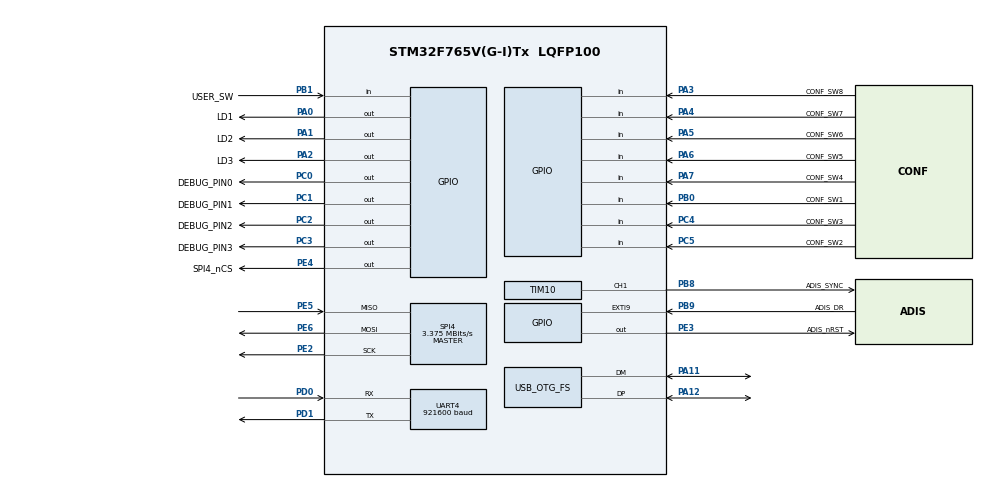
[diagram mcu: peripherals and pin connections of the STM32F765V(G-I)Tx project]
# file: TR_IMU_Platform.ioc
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CORTEX_M7.CPU_DCache=Disabled
CORTEX_M7.CPU_ICache=Enabled
CORTEX_M7.PREFETCH_ENABLE=0
Dma.Request0=UART4_RX
Dma.Request1=UART4_TX
Dma.Request2=SPI4_RX
Dma.SPI4_RX.2.Direction=DMA_PERIPH_TO_MEMORY
Dma.SPI4_RX.2.FIFOMode=DMA_FIFOMODE_DISABLE
Dma.SPI4_RX.2.Instance=DMA2_Stream0
Dma.SPI4_RX.2.MemDataAlignment=DMA_MDATAALIGN_HALFWORD
Dma.SPI4_RX.2.MemInc=DMA_MINC_ENABLE
Dma.SPI4_RX.2.Mode=DMA_NORMAL
Dma.SPI4_RX.2.PeriphDataAlignment=DMA_PDATAALIGN_HALFWORD
Dma.SPI4_RX.2.PeriphInc=DMA_PINC_DISABLE
Dma.SPI4_RX.2.Priority=DMA_PRIORITY_HIGH
Dma.UART4_RX.0.Direction=DMA_PERIPH_TO_MEMORY
Dma.UART4_RX.0.FIFOMode=DMA_FIFOMODE_DISABLE
Dma.UART4_RX.0.Instance=DMA1_Stream2
Dma.UART4_RX.0.MemDataAlignment=DMA_MDATAALIGN_BYTE
Dma.UART4_RX.0.MemInc=DMA_MINC_ENABLE
Dma.UART4_RX.0.Mode=DMA_CIRCULAR
Dma.UART4_RX.0.PeriphDataAlignment=DMA_PDATAALIGN_BYTE
Dma.UART4_RX.0.PeriphInc=DMA_PINC_DISABLE
Dma.UART4_RX.0.Priority=DMA_PRIORITY_HIGH
Dma.UART4_TX.1.Direction=DMA_MEMORY_TO_PERIPH
Dma.UART4_TX.1.FIFOMode=DMA_FIFOMODE_DISABLE
Dma.UART4_TX.1.Instance=DMA1_Stream4
Dma.UART4_TX.1.MemDataAlignment=DMA_MDATAALIGN_BYTE
Dma.UART4_TX.1.MemInc=DMA_MINC_ENABLE
Dma.UART4_TX.1.Mode=DMA_NORMAL
Dma.UART4_TX.1.PeriphDataAlignment=DMA_PDATAALIGN_BYTE
Dma.UART4_TX.1.PeriphInc=DMA_PINC_DISABLE
Dma.UART4_TX.1.Priority=DMA_PRIORITY_LOW
IWDG.Prescaler=IWDG_PRESCALER_16
Mcu.Family=STM32F7
Mcu.Name=STM32F765V(G-I)Tx
Mcu.Package=LQFP100
NVIC.DMA1_Stream2_IRQn=true\:3\:0\:true\:false\:true\:false\:true\:true
NVIC.DMA1_Stream4_IRQn=true\:3\:0\:true\:false\:true\:false\:true\:true
NVIC.DMA2_Stream0_IRQn=true\:0\:0\:false\:false\:true\:false\:true\:true
NVIC.EXTI9_5_IRQn=true\:2\:0\:true\:false\:true\:true\:true\:true
NVIC.OTG_FS_IRQn=true\:0\:0\:false\:false\:true\:false\:true\:true
NVIC.PriorityGroup=NVIC_PRIORITYGROUP_4
NVIC.UART4_IRQn=true\:1\:0\:true\:false\:true\:true\:true\:true
PA0/WKUP.GPIO_Label=LD1
PA0/WKUP.GPIO_ModeDefaultOutputPP=GPIO_MODE_OUTPUT_OD
PA0/WKUP.GPIO_PuPd=GPIO_NOPULL
PA0/WKUP.GPIO_Speed=GPIO_SPEED_FREQ_VERY_HIGH
PA0/WKUP.PinState=GPIO_PIN_SET
PA0/WKUP.Signal=GPIO_Output
PA1.GPIO_Label=LD2
PA1.GPIO_ModeDefaultOutputPP=GPIO_MODE_OUTPUT_OD
PA1.GPIO_PuPd=GPIO_NOPULL
PA1.GPIO_Speed=GPIO_SPEED_FREQ_VERY_HIGH
PA1.PinState=GPIO_PIN_SET
PA1.Signal=GPIO_Output
PA11.Mode=Device_Only
PA11.Signal=USB_OTG_FS_DM
PA12.Mode=Device_Only
PA12.Signal=USB_OTG_FS_DP
PA13.Mode=Serial_Wire
PA13.Signal=SYS_JTMS-SWDIO
PA14.Mode=Serial_Wire
PA14.Signal=SYS_JTCK-SWCLK
PA2.GPIO_Label=LD3
PA2.GPIO_ModeDefaultOutputPP=GPIO_MODE_OUTPUT_OD
PA2.GPIO_PuPd=GPIO_NOPULL
PA2.GPIO_Speed=GPIO_SPEED_FREQ_VERY_HIGH
PA2.PinState=GPIO_PIN_SET
PA2.Signal=GPIO_Output
PA3.GPIO_Label=CONF_SW8
PA3.GPIO_Mode=GPIO_MODE_INPUT
PA3.GPIO_PuPd=GPIO_NOPULL
PA3.Signal=GPIO_Input
PA4.GPIO_Label=CONF_SW7
PA4.GPIO_Mode=GPIO_MODE_INPUT
PA4.GPIO_PuPd=GPIO_NOPULL
PA4.Signal=GPIO_Input
PA5.GPIO_Label=CONF_SW6
PA5.GPIO_Mode=GPIO_MODE_INPUT
PA5.GPIO_PuPd=GPIO_NOPULL
PA5.Signal=GPIO_Input
PA6.GPIO_Label=CONF_SW5
PA6.GPIO_Mode=GPIO_MODE_INPUT
PA6.GPIO_PuPd=GPIO_NOPULL
PA6.Signal=GPIO_Input
PA7.GPIO_Label=CONF_SW4
PA7.GPIO_Mode=GPIO_MODE_INPUT
PA7.GPIO_PuPd=GPIO_NOPULL
PA7.Signal=GPIO_Input
PB0.GPIO_Label=CONF_SW1
PB0.GPIO_Mode=GPIO_MODE_INPUT
PB0.GPIO_PuPd=GPIO_NOPULL
PB0.Signal=GPIO_Input
PB1.GPIO_Label=USER_SW
PB1.Signal=GPIO_Input
PB8.GPIO_Label=ADIS_SYNC
PB8.GPIO_Speed=GPIO_SPEED_FREQ_VERY_HIGH
PB8.Signal=S_TIM10_CH1
PB9.GPIO_Label=ADIS_DR
PB9.GPIO_PuPd=GPIO_PULLUP
PB9.Signal=GPXTI9
PC0.GPIO_Label=DEBUG_PIN0
PC0.GPIO_Speed=GPIO_SPEED_FREQ_VERY_HIGH
PC0.Signal=GPIO_Output
PC1.GPIO_Label=DEBUG_PIN1
PC1.GPIO_Speed=GPIO_SPEED_FREQ_VERY_HIGH
PC1.Signal=GPIO_Output
PC2.GPIO_Label=DEBUG_PIN2
PC2.GPIO_Speed=GPIO_SPEED_FREQ_VERY_HIGH
PC2.Signal=GPIO_Output
PC3.GPIO_Label=DEBUG_PIN3
PC3.GPIO_Speed=GPIO_SPEED_FREQ_VERY_HIGH
PC3.Signal=GPIO_Output
PC4.GPIO_Label=CONF_SW3
PC4.Signal=GPIO_Input
PC5.GPIO_Label=CONF_SW2
PC5.Signal=GPIO_Input
PD0.Mode=Asynchronous
PD0.Signal=UART4_RX
PD1.Mode=Asynchronous
PD1.Signal=UART4_TX
PE2.Mode=Full_Duplex_Master
PE2.Signal=SPI4_SCK
PE3.GPIO_Label=ADIS_nRST
PE3.GPIO_Speed=GPIO_SPEED_FREQ_VERY_HIGH
PE3.PinState=GPIO_PIN_SET
PE3.Signal=GPIO_Output
PE4.GPIO_Label=SPI4_nCS
PE4.GPIO_Speed=GPIO_SPEED_FREQ_VERY_HIGH
PE4.PinState=GPIO_PIN_SET
PE4.Signal=GPIO_Output
PE5.Mode=Full_Duplex_Master
PE5.Signal=SPI4_MISO
PE6.Mode=Full_Duplex_Master
PE6.Signal=SPI4_MOSI
PH0/OSC_IN.Mode=HSE-External-Oscillator
PH0/OSC_IN.Signal=RCC_OSC_IN
PH1/OSC_OUT.Mode=HSE-External-Oscillator
PH1/OSC_OUT.Signal=RCC_OSC_OUT
ProjectManager.HeapSize=0x400
ProjectManager.StackSize=0x400
ProjectManager.TargetToolchain=STM32CubeIDE
RCC.AHBFreq_Value=216000000
RCC.APB1CLKDivider=RCC_HCLK_DIV4
RCC.APB1Freq_Value=54000000
RCC.APB1TimFreq_Value=108000000
RCC.APB2CLKDivider=RCC_HCLK_DIV2
RCC.APB2Freq_Value=108000000
RCC.APB2TimFreq_Value=216000000
RCC.CortexFreq_Value=216000000
RCC.HCLKFreq_Value=216000000
RCC.HSE_VALUE=8000000
RCC.HSI_VALUE=16000000
RCC.LSE_VALUE=32768
RCC.PLL48CLockSelection=RCC_CLK48SOURCE_PLLSAIP
RCC.PLLM=4
RCC.PLLN=216
RCC.PLLQ=9
RCC.PLLSAIN=96
RCC.PLLSAIP=RCC_PLLSAIP_DIV4
RCC.SYSCLKFreq_VALUE=216000000
RCC.SYSCLKSource=RCC_SYSCLKSOURCE_PLLCLK
RCC.USBFreq_Value=48000000
RCC.VCOOutputFreq_Value=432000000
SH.S_TIM10_CH1.0=TIM10_CH1,PWM Generation1 CH1
SPI4.BaudRatePrescaler=SPI_BAUDRATEPRESCALER_32
SPI4.CLKPhase=SPI_PHASE_2EDGE
SPI4.CLKPolarity=SPI_POLARITY_HIGH
SPI4.CalculateBaudRate=3.375 MBits/s
SPI4.DataSize=SPI_DATASIZE_16BIT
SPI4.Direction=SPI_DIRECTION_2LINES
SPI4.Mode=SPI_MODE_MASTER
SPI4.VirtualType=VM_MASTER
TIM10.AutoReloadPreload=TIM_AUTORELOAD_PRELOAD_ENABLE
TIM10.Channel=TIM_CHANNEL_1
TIM10.Period=26999
TIM10.Prescaler=1
UART4.BaudRate=921600
USB_DEVICE.CLASS_NAME_FS=CDC
USB_DEVICE.VirtualMode-CDC_FS=Cdc
USB_DEVICE.VirtualModeFS=Cdc_FS
USB_OTG_FS.VirtualMode=Device_Only
VP_IWDG_VS_IWDG.Mode=IWDG_Activate
VP_TIM10_VS_ClockSourceINT.Mode=Enable_Timer
VP_USB_DEVICE_VS_USB_DEVICE_CDC_FS.Mode=CDC_FS
board=custom

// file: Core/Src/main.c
/* USER CODE BEGIN Header */
/**
  ******************************************************************************
  * @file           : main.c
  * @brief          : Main program body
  ******************************************************************************
  * @attention
  *
  * Copyright (c) 2023 STMicroelectronics.
  * All rights reserved.
  *
  * This software is licensed under terms that can be found in the LICENSE file
  * in the root directory of this software component.
  * If no LICENSE file comes with this software, it is provided AS-IS.
  *
  ******************************************************************************
  */
/* USER CODE END Header */
#include "main.h"
#include "usb_device.h"

/* USER CODE BEGIN Includes */
#include "libraries.h"
/* USER CODE END Includes */

void SystemClock_Config(void);
void PeriphCommonClock_Config(void);
static void MX_GPIO_Init(void);
static void MX_DMA_Init(void);
static void MX_SPI4_Init(void);
static void MX_UART4_Init(void);
static void MX_TIM10_Init(void);

int main(void)
{

  /* Enable the CPU Cache */

  /* Enable I-Cache---------------------------------------------------------*/
  SCB_EnableICache();

  /* MCU Configuration--------------------------------------------------------*/

  /* Reset of all peripherals, Initializes the Flash interface and the Systick. */
  HAL_Init();

  /* Configure the system clock */
  SystemClock_Config();

  /* Configure the peripherals common clocks */
  PeriphCommonClock_Config();

  /* Initialize all configured peripherals */
  MX_GPIO_Init();
  MX_DMA_Init();
  MX_SPI4_Init();
  MX_USB_DEVICE_Init();
  MX_UART4_Init();
  MX_TIM10_Init();
  /* USER CODE BEGIN 2 */
  EXTI_Stop();
  setup();
  /* USER CODE END 2 */

  /* Infinite loop */
  /* USER CODE BEGIN WHILE */
  while (1)
  {
    loop();
    /* USER CODE END WHILE */

  }
}

void SystemClock_Config(void)
{
  LL_FLASH_SetLatency(LL_FLASH_LATENCY_7);
  while(LL_FLASH_GetLatency()!= LL_FLASH_LATENCY_7)
  {
  }
  LL_PWR_SetRegulVoltageScaling(LL_PWR_REGU_VOLTAGE_SCALE1);
  LL_PWR_EnableOverDriveMode();
  LL_RCC_HSE_Enable();

   /* Wait till HSE is ready */
  while(LL_RCC_HSE_IsReady() != 1)
  {

  }
  LL_RCC_LSI_Enable();

   /* Wait till LSI is ready */
  while(LL_RCC_LSI_IsReady() != 1)
  {

  }
  LL_RCC_PLL_ConfigDomain_SYS(LL_RCC_PLLSOURCE_HSE, LL_RCC_PLLM_DIV_4, 216, LL_RCC_PLLP_DIV_2);
  LL_RCC_PLL_Enable();

   /* Wait till PLL is ready */
  while(LL_RCC_PLL_IsReady() != 1)
  {

  }
  while (LL_PWR_IsActiveFlag_VOS() == 0)
  {
  }
  LL_RCC_SetAHBPrescaler(LL_RCC_SYSCLK_DIV_1);
  LL_RCC_SetAPB1Prescaler(LL_RCC_APB1_DIV_4);
  LL_RCC_SetAPB2Prescaler(LL_RCC_APB2_DIV_2);
  LL_RCC_SetSysClkSource(LL_RCC_SYS_CLKSOURCE_PLL);

   /* Wait till System clock is ready */
  while(LL_RCC_GetSysClkSource() != LL_RCC_SYS_CLKSOURCE_STATUS_PLL)
  {

  }
  LL_SetSystemCoreClock(216000000);

   /* Update the time base */
  if (HAL_InitTick (TICK_INT_PRIORITY) != HAL_OK)
  {
    Error_Handler();
  }

   /* Set Timers Clock Prescalers */
  LL_RCC_SetTIMPrescaler(LL_RCC_TIM_PRESCALER_TWICE);
}

void PeriphCommonClock_Config(void)
{
  LL_RCC_PLLSAI_ConfigDomain_48M(LL_RCC_PLLSOURCE_HSE, LL_RCC_PLLM_DIV_4, 96, LL_RCC_PLLSAIP_DIV_4);
  LL_RCC_PLLSAI_Enable();

   /* Wait till PLL is ready */
  while(LL_RCC_PLLSAI_IsReady() != 1)
  {

  }
}

static void MX_SPI4_Init(void)
{

  LL_SPI_InitTypeDef SPI_InitStruct = {0};

  LL_GPIO_InitTypeDef GPIO_InitStruct = {0};

  /* Peripheral clock enable */
  LL_APB2_GRP1_EnableClock(LL_APB2_GRP1_PERIPH_SPI4);

  LL_AHB1_GRP1_EnableClock(LL_AHB1_GRP1_PERIPH_GPIOE);
  /**SPI4 GPIO Configuration
  PE2   ------> SPI4_SCK
  PE5   ------> SPI4_MISO
  PE6   ------> SPI4_MOSI
  */
  GPIO_InitStruct.Pin = LL_GPIO_PIN_2;
  GPIO_InitStruct.Mode = LL_GPIO_MODE_ALTERNATE;
  GPIO_InitStruct.Speed = LL_GPIO_SPEED_FREQ_VERY_HIGH;
  GPIO_InitStruct.OutputType = LL_GPIO_OUTPUT_PUSHPULL;
  GPIO_InitStruct.Pull = LL_GPIO_PULL_NO;
  GPIO_InitStruct.Alternate = LL_GPIO_AF_5;
  LL_GPIO_Init(GPIOE, &GPIO_InitStruct);

  GPIO_InitStruct.Pin = LL_GPIO_PIN_5;
  GPIO_InitStruct.Mode = LL_GPIO_MODE_ALTERNATE;
  GPIO_InitStruct.Speed = LL_GPIO_SPEED_FREQ_VERY_HIGH;
  GPIO_InitStruct.OutputType = LL_GPIO_OUTPUT_PUSHPULL;
  GPIO_InitStruct.Pull = LL_GPIO_PULL_NO;
  GPIO_InitStruct.Alternate = LL_GPIO_AF_5;
  LL_GPIO_Init(GPIOE, &GPIO_InitStruct);

  GPIO_InitStruct.Pin = LL_GPIO_PIN_6;
  GPIO_InitStruct.Mode = LL_GPIO_MODE_ALTERNATE;
  GPIO_InitStruct.Speed = LL_GPIO_SPEED_FREQ_VERY_HIGH;
  GPIO_InitStruct.OutputType = LL_GPIO_OUTPUT_PUSHPULL;
  GPIO_InitStruct.Pull = LL_GPIO_PULL_NO;
  GPIO_InitStruct.Alternate = LL_GPIO_AF_5;
  LL_GPIO_Init(GPIOE, &GPIO_InitStruct);

  /* SPI4 DMA Init */

  /* SPI4_RX Init */
  LL_DMA_SetChannelSelection(DMA2, LL_DMA_STREAM_0, LL_DMA_CHANNEL_4);

  LL_DMA_SetDataTransferDirection(DMA2, LL_DMA_STREAM_0, LL_DMA_DIRECTION_PERIPH_TO_MEMORY);

  LL_DMA_SetStreamPriorityLevel(DMA2, LL_DMA_STREAM_0, LL_DMA_PRIORITY_HIGH);

  LL_DMA_SetMode(DMA2, LL_DMA_STREAM_0, LL_DMA_MODE_NORMAL);

  LL_DMA_SetPeriphIncMode(DMA2, LL_DMA_STREAM_0, LL_DMA_PERIPH_NOINCREMENT);

  LL_DMA_SetMemoryIncMode(DMA2, LL_DMA_STREAM_0, LL_DMA_MEMORY_INCREMENT);

  LL_DMA_SetPeriphSize(DMA2, LL_DMA_STREAM_0, LL_DMA_PDATAALIGN_HALFWORD);

  LL_DMA_SetMemorySize(DMA2, LL_DMA_STREAM_0, LL_DMA_MDATAALIGN_HALFWORD);

  LL_DMA_DisableFifoMode(DMA2, LL_DMA_STREAM_0);

  /* SPI4 parameter configuration*/
  SPI_InitStruct.TransferDirection = LL_SPI_FULL_DUPLEX;
  SPI_InitStruct.Mode = LL_SPI_MODE_MASTER;
  SPI_InitStruct.DataWidth = LL_SPI_DATAWIDTH_16BIT;
  SPI_InitStruct.ClockPolarity = LL_SPI_POLARITY_HIGH;
  SPI_InitStruct.ClockPhase = LL_SPI_PHASE_2EDGE;
  SPI_InitStruct.NSS = LL_SPI_NSS_SOFT;
  SPI_InitStruct.BaudRate = LL_SPI_BAUDRATEPRESCALER_DIV32;
  SPI_InitStruct.BitOrder = LL_SPI_MSB_FIRST;
  SPI_InitStruct.CRCCalculation = LL_SPI_CRCCALCULATION_DISABLE;
  SPI_InitStruct.CRCPoly = 7;
  LL_SPI_Init(SPI4, &SPI_InitStruct);
  LL_SPI_SetStandard(SPI4, LL_SPI_PROTOCOL_MOTOROLA);
  LL_SPI_DisableNSSPulseMgt(SPI4);

}

static void MX_TIM10_Init(void)
{

  LL_TIM_InitTypeDef TIM_InitStruct = {0};
  LL_TIM_OC_InitTypeDef TIM_OC_InitStruct = {0};

  LL_GPIO_InitTypeDef GPIO_InitStruct = {0};

  /* Peripheral clock enable */
  LL_APB2_GRP1_EnableClock(LL_APB2_GRP1_PERIPH_TIM10);

  TIM_InitStruct.Prescaler = 1;
  TIM_InitStruct.CounterMode = LL_TIM_COUNTERMODE_UP;
  TIM_InitStruct.Autoreload = 26999;
  TIM_InitStruct.ClockDivision = LL_TIM_CLOCKDIVISION_DIV1;
  LL_TIM_Init(TIM10, &TIM_InitStruct);
  LL_TIM_EnableARRPreload(TIM10);
  LL_TIM_OC_EnablePreload(TIM10, LL_TIM_CHANNEL_CH1);
  TIM_OC_InitStruct.OCMode = LL_TIM_OCMODE_PWM1;
  TIM_OC_InitStruct.OCState = LL_TIM_OCSTATE_DISABLE;
  TIM_OC_InitStruct.OCNState = LL_TIM_OCSTATE_DISABLE;
  TIM_OC_InitStruct.CompareValue = 0;
  TIM_OC_InitStruct.OCPolarity = LL_TIM_OCPOLARITY_HIGH;
  LL_TIM_OC_Init(TIM10, LL_TIM_CHANNEL_CH1, &TIM_OC_InitStruct);
  LL_TIM_OC_DisableFast(TIM10, LL_TIM_CHANNEL_CH1);
  LL_AHB1_GRP1_EnableClock(LL_AHB1_GRP1_PERIPH_GPIOB);
  /**TIM10 GPIO Configuration
  PB8   ------> TIM10_CH1
  */
  GPIO_InitStruct.Pin = ADIS_SYNC_Pin;
  GPIO_InitStruct.Mode = LL_GPIO_MODE_ALTERNATE;
  GPIO_InitStruct.Speed = LL_GPIO_SPEED_FREQ_VERY_HIGH;
  GPIO_InitStruct.OutputType = LL_GPIO_OUTPUT_PUSHPULL;
  GPIO_InitStruct.Pull = LL_GPIO_PULL_NO;
  GPIO_InitStruct.Alternate = LL_GPIO_AF_3;
  LL_GPIO_Init(ADIS_SYNC_GPIO_Port, &GPIO_InitStruct);

}

static void MX_UART4_Init(void)
{

  LL_USART_InitTypeDef USART_InitStruct = {0};

  LL_GPIO_InitTypeDef GPIO_InitStruct = {0};

  LL_RCC_SetUARTClockSource(LL_RCC_UART4_CLKSOURCE_PCLK1);

  /* Peripheral clock enable */
  LL_APB1_GRP1_EnableClock(LL_APB1_GRP1_PERIPH_UART4);

  LL_AHB1_GRP1_EnableClock(LL_AHB1_GRP1_PERIPH_GPIOD);
  /**UART4 GPIO Configuration
  PD0   ------> UART4_RX
  PD1   ------> UART4_TX
  */
  GPIO_InitStruct.Pin = LL_GPIO_PIN_0;
  GPIO_InitStruct.Mode = LL_GPIO_MODE_ALTERNATE;
  GPIO_InitStruct.Speed = LL_GPIO_SPEED_FREQ_VERY_HIGH;
  GPIO_InitStruct.OutputType = LL_GPIO_OUTPUT_PUSHPULL;
  GPIO_InitStruct.Pull = LL_GPIO_PULL_NO;
  GPIO_InitStruct.Alternate = LL_GPIO_AF_8;
  LL_GPIO_Init(GPIOD, &GPIO_InitStruct);

  GPIO_InitStruct.Pin = LL_GPIO_PIN_1;
  GPIO_InitStruct.Mode = LL_GPIO_MODE_ALTERNATE;
  GPIO_InitStruct.Speed = LL_GPIO_SPEED_FREQ_VERY_HIGH;
  GPIO_InitStruct.OutputType = LL_GPIO_OUTPUT_PUSHPULL;
  GPIO_InitStruct.Pull = LL_GPIO_PULL_NO;
  GPIO_InitStruct.Alternate = LL_GPIO_AF_8;
  LL_GPIO_Init(GPIOD, &GPIO_InitStruct);

  /* UART4 DMA Init */

  /* UART4_RX Init */
  LL_DMA_SetChannelSelection(DMA1, LL_DMA_STREAM_2, LL_DMA_CHANNEL_4);

  LL_DMA_SetDataTransferDirection(DMA1, LL_DMA_STREAM_2, LL_DMA_DIRECTION_PERIPH_TO_MEMORY);

  LL_DMA_SetStreamPriorityLevel(DMA1, LL_DMA_STREAM_2, LL_DMA_PRIORITY_HIGH);

  LL_DMA_SetMode(DMA1, LL_DMA_STREAM_2, LL_DMA_MODE_CIRCULAR);

  LL_DMA_SetPeriphIncMode(DMA1, LL_DMA_STREAM_2, LL_DMA_PERIPH_NOINCREMENT);

  LL_DMA_SetMemoryIncMode(DMA1, LL_DMA_STREAM_2, LL_DMA_MEMORY_INCREMENT);

  LL_DMA_SetPeriphSize(DMA1, LL_DMA_STREAM_2, LL_DMA_PDATAALIGN_BYTE);

  LL_DMA_SetMemorySize(DMA1, LL_DMA_STREAM_2, LL_DMA_MDATAALIGN_BYTE);

  LL_DMA_DisableFifoMode(DMA1, LL_DMA_STREAM_2);

  /* UART4_TX Init */
  LL_DMA_SetChannelSelection(DMA1, LL_DMA_STREAM_4, LL_DMA_CHANNEL_4);

  LL_DMA_SetDataTransferDirection(DMA1, LL_DMA_STREAM_4, LL_DMA_DIRECTION_MEMORY_TO_PERIPH);

  LL_DMA_SetStreamPriorityLevel(DMA1, LL_DMA_STREAM_4, LL_DMA_PRIORITY_LOW);

  LL_DMA_SetMode(DMA1, LL_DMA_STREAM_4, LL_DMA_MODE_NORMAL);

  LL_DMA_SetPeriphIncMode(DMA1, LL_DMA_STREAM_4, LL_DMA_PERIPH_NOINCREMENT);

  LL_DMA_SetMemoryIncMode(DMA1, LL_DMA_STREAM_4, LL_DMA_MEMORY_INCREMENT);

  LL_DMA_SetPeriphSize(DMA1, LL_DMA_STREAM_4, LL_DMA_PDATAALIGN_BYTE);

  LL_DMA_SetMemorySize(DMA1, LL_DMA_STREAM_4, LL_DMA_MDATAALIGN_BYTE);

  LL_DMA_DisableFifoMode(DMA1, LL_DMA_STREAM_4);

  /* UART4 interrupt Init */
  NVIC_SetPriority(UART4_IRQn, NVIC_EncodePriority(NVIC_GetPriorityGrouping(),1, 0));
  NVIC_EnableIRQ(UART4_IRQn);

  USART_InitStruct.BaudRate = 921600;
  USART_InitStruct.DataWidth = LL_USART_DATAWIDTH_8B;
  USART_InitStruct.StopBits = LL_USART_STOPBITS_1;
  USART_InitStruct.Parity = LL_USART_PARITY_NONE;
  USART_InitStruct.TransferDirection = LL_USART_DIRECTION_TX_RX;
  USART_InitStruct.HardwareFlowControl = LL_USART_HWCONTROL_NONE;
  USART_InitStruct.OverSampling = LL_USART_OVERSAMPLING_16;
  LL_USART_Init(UART4, &USART_InitStruct);
  LL_USART_ConfigAsyncMode(UART4);
  LL_USART_Enable(UART4);

}

static void MX_DMA_Init(void)
{

  /* Init with LL driver */
  /* DMA controller clock enable */
  LL_AHB1_GRP1_EnableClock(LL_AHB1_GRP1_PERIPH_DMA1);
  LL_AHB1_GRP1_EnableClock(LL_AHB1_GRP1_PERIPH_DMA2);

  /* DMA interrupt init */
  /* DMA1_Stream2_IRQn interrupt configuration */
  NVIC_SetPriority(DMA1_Stream2_IRQn, NVIC_EncodePriority(NVIC_GetPriorityGrouping(),3, 0));
  NVIC_EnableIRQ(DMA1_Stream2_IRQn);
  /* DMA1_Stream4_IRQn interrupt configuration */
  NVIC_SetPriority(DMA1_Stream4_IRQn, NVIC_EncodePriority(NVIC_GetPriorityGrouping(),3, 0));
  NVIC_EnableIRQ(DMA1_Stream4_IRQn);
  /* DMA2_Stream0_IRQn interrupt configuration */
  NVIC_SetPriority(DMA2_Stream0_IRQn, NVIC_EncodePriority(NVIC_GetPriorityGrouping(),0, 0));
  NVIC_EnableIRQ(DMA2_Stream0_IRQn);

}

static void MX_GPIO_Init(void)
{
  LL_EXTI_InitTypeDef EXTI_InitStruct = {0};
  LL_GPIO_InitTypeDef GPIO_InitStruct = {0};

  /* GPIO Ports Clock Enable */
  LL_AHB1_GRP1_EnableClock(LL_AHB1_GRP1_PERIPH_GPIOE);
  LL_AHB1_GRP1_EnableClock(LL_AHB1_GRP1_PERIPH_GPIOH);
  LL_AHB1_GRP1_EnableClock(LL_AHB1_GRP1_PERIPH_GPIOC);
  LL_AHB1_GRP1_EnableClock(LL_AHB1_GRP1_PERIPH_GPIOA);
  LL_AHB1_GRP1_EnableClock(LL_AHB1_GRP1_PERIPH_GPIOB);
  LL_AHB1_GRP1_EnableClock(LL_AHB1_GRP1_PERIPH_GPIOD);

  /**/
  LL_GPIO_SetOutputPin(ADIS_nRST_GPIO_Port, ADIS_nRST_Pin);

  /**/
  LL_GPIO_SetOutputPin(SPI4_nCS_GPIO_Port, SPI4_nCS_Pin);

  /**/
  LL_GPIO_SetOutputPin(LD1_GPIO_Port, LD1_Pin);

  /**/
  LL_GPIO_SetOutputPin(LD2_GPIO_Port, LD2_Pin);

  /**/
  LL_GPIO_SetOutputPin(LD3_GPIO_Port, LD3_Pin);

  /**/
  LL_GPIO_ResetOutputPin(DEBUG_PIN0_GPIO_Port, DEBUG_PIN0_Pin);

  /**/
  LL_GPIO_ResetOutputPin(DEBUG_PIN1_GPIO_Port, DEBUG_PIN1_Pin);

  /**/
  LL_GPIO_ResetOutputPin(DEBUG_PIN2_GPIO_Port, DEBUG_PIN2_Pin);

  /**/
  LL_GPIO_ResetOutputPin(DEBUG_PIN3_GPIO_Port, DEBUG_PIN3_Pin);

  /**/
  GPIO_InitStruct.Pin = ADIS_nRST_Pin;
  GPIO_InitStruct.Mode = LL_GPIO_MODE_OUTPUT;
  GPIO_InitStruct.Speed = LL_GPIO_SPEED_FREQ_VERY_HIGH;
  GPIO_InitStruct.OutputType = LL_GPIO_OUTPUT_PUSHPULL;
  GPIO_InitStruct.Pull = LL_GPIO_PULL_NO;
  LL_GPIO_Init(ADIS_nRST_GPIO_Port, &GPIO_InitStruct);

  /**/
  GPIO_InitStruct.Pin = SPI4_nCS_Pin;
  GPIO_InitStruct.Mode = LL_GPIO_MODE_OUTPUT;
  GPIO_InitStruct.Speed = LL_GPIO_SPEED_FREQ_VERY_HIGH;
  GPIO_InitStruct.OutputType = LL_GPIO_OUTPUT_PUSHPULL;
  GPIO_InitStruct.Pull = LL_GPIO_PULL_NO;
  LL_GPIO_Init(SPI4_nCS_GPIO_Port, &GPIO_InitStruct);

  /**/
  GPIO_InitStruct.Pin = DEBUG_PIN0_Pin;
  GPIO_InitStruct.Mode = LL_GPIO_MODE_OUTPUT;
  GPIO_InitStruct.Speed = LL_GPIO_SPEED_FREQ_VERY_HIGH;
  GPIO_InitStruct.OutputType = LL_GPIO_OUTPUT_PUSHPULL;
  GPIO_InitStruct.Pull = LL_GPIO_PULL_NO;
  LL_GPIO_Init(DEBUG_PIN0_GPIO_Port, &GPIO_InitStruct);

  /**/
  GPIO_InitStruct.Pin = DEBUG_PIN1_Pin;
  GPIO_InitStruct.Mode = LL_GPIO_MODE_OUTPUT;
  GPIO_InitStruct.Speed = LL_GPIO_SPEED_FREQ_VERY_HIGH;
  GPIO_InitStruct.OutputType = LL_GPIO_OUTPUT_PUSHPULL;
  GPIO_InitStruct.Pull = LL_GPIO_PULL_NO;
  LL_GPIO_Init(DEBUG_PIN1_GPIO_Port, &GPIO_InitStruct);

  /**/
  GPIO_InitStruct.Pin = DEBUG_PIN2_Pin;
  GPIO_InitStruct.Mode = LL_GPIO_MODE_OUTPUT;
  GPIO_InitStruct.Speed = LL_GPIO_SPEED_FREQ_VERY_HIGH;
  GPIO_InitStruct.OutputType = LL_GPIO_OUTPUT_PUSHPULL;
  GPIO_InitStruct.Pull = LL_GPIO_PULL_NO;
  LL_GPIO_Init(DEBUG_PIN2_GPIO_Port, &GPIO_InitStruct);

  /**/
  GPIO_InitStruct.Pin = DEBUG_PIN3_Pin;
  GPIO_InitStruct.Mode = LL_GPIO_MODE_OUTPUT;
  GPIO_InitStruct.Speed = LL_GPIO_SPEED_FREQ_VERY_HIGH;
  GPIO_InitStruct.OutputType = LL_GPIO_OUTPUT_PUSHPULL;
  GPIO_InitStruct.Pull = LL_GPIO_PULL_NO;
  LL_GPIO_Init(DEBUG_PIN3_GPIO_Port, &GPIO_InitStruct);

  /**/
  GPIO_InitStruct.Pin = LD1_Pin;
  GPIO_InitStruct.Mode = LL_GPIO_MODE_OUTPUT;
  GPIO_InitStruct.Speed = LL_GPIO_SPEED_FREQ_VERY_HIGH;
  GPIO_InitStruct.OutputType = LL_GPIO_OUTPUT_OPENDRAIN;
  GPIO_InitStruct.Pull = LL_GPIO_PULL_NO;
  LL_GPIO_Init(LD1_GPIO_Port, &GPIO_InitStruct);

  /**/
  GPIO_InitStruct.Pin = LD2_Pin;
  GPIO_InitStruct.Mode = LL_GPIO_MODE_OUTPUT;
  GPIO_InitStruct.Speed = LL_GPIO_SPEED_FREQ_VERY_HIGH;
  GPIO_InitStruct.OutputType = LL_GPIO_OUTPUT_OPENDRAIN;
  GPIO_InitStruct.Pull = LL_GPIO_PULL_NO;
  LL_GPIO_Init(LD2_GPIO_Port, &GPIO_InitStruct);

  /**/
  GPIO_InitStruct.Pin = LD3_Pin;
  GPIO_InitStruct.Mode = LL_GPIO_MODE_OUTPUT;
  GPIO_InitStruct.Speed = LL_GPIO_SPEED_FREQ_VERY_HIGH;
  GPIO_InitStruct.OutputType = LL_GPIO_OUTPUT_OPENDRAIN;
  GPIO_InitStruct.Pull = LL_GPIO_PULL_NO;
  LL_GPIO_Init(LD3_GPIO_Port, &GPIO_InitStruct);

  /**/
  GPIO_InitStruct.Pin = CONF_SW8_Pin;
  GPIO_InitStruct.Mode = LL_GPIO_MODE_INPUT;
  GPIO_InitStruct.Pull = LL_GPIO_PULL_NO;
  LL_GPIO_Init(CONF_SW8_GPIO_Port, &GPIO_InitStruct);

  /**/
  GPIO_InitStruct.Pin = CONF_SW7_Pin;
  GPIO_InitStruct.Mode = LL_GPIO_MODE_INPUT;
  GPIO_InitStruct.Pull = LL_GPIO_PULL_NO;
  LL_GPIO_Init(CONF_SW7_GPIO_Port, &GPIO_InitStruct);

  /**/
  GPIO_InitStruct.Pin = CONF_SW6_Pin;
  GPIO_InitStruct.Mode = LL_GPIO_MODE_INPUT;
  GPIO_InitStruct.Pull = LL_GPIO_PULL_NO;
  LL_GPIO_Init(CONF_SW6_GPIO_Port, &GPIO_InitStruct);

  /**/
  GPIO_InitStruct.Pin = CONF_SW5_Pin;
  GPIO_InitStruct.Mode = LL_GPIO_MODE_INPUT;
  GPIO_InitStruct.Pull = LL_GPIO_PULL_NO;
  LL_GPIO_Init(CONF_SW5_GPIO_Port, &GPIO_InitStruct);

  /**/
  GPIO_InitStruct.Pin = CONF_SW4_Pin;
  GPIO_InitStruct.Mode = LL_GPIO_MODE_INPUT;
  GPIO_InitStruct.Pull = LL_GPIO_PULL_NO;
  LL_GPIO_Init(CONF_SW4_GPIO_Port, &GPIO_InitStruct);

  /**/
  GPIO_InitStruct.Pin = CONF_SW3_Pin;
  GPIO_InitStruct.Mode = LL_GPIO_MODE_INPUT;
  GPIO_InitStruct.Pull = LL_GPIO_PULL_NO;
  LL_GPIO_Init(CONF_SW3_GPIO_Port, &GPIO_InitStruct);

  /**/
  GPIO_InitStruct.Pin = CONF_SW2_Pin;
  GPIO_InitStruct.Mode = LL_GPIO_MODE_INPUT;
  GPIO_InitStruct.Pull = LL_GPIO_PULL_NO;
  LL_GPIO_Init(CONF_SW2_GPIO_Port, &GPIO_InitStruct);

  /**/
  GPIO_InitStruct.Pin = CONF_SW1_Pin;
  GPIO_InitStruct.Mode = LL_GPIO_MODE_INPUT;
  GPIO_InitStruct.Pull = LL_GPIO_PULL_NO;
  LL_GPIO_Init(CONF_SW1_GPIO_Port, &GPIO_InitStruct);

  /**/
  GPIO_InitStruct.Pin = USER_SW_Pin;
  GPIO_InitStruct.Mode = LL_GPIO_MODE_INPUT;
  GPIO_InitStruct.Pull = LL_GPIO_PULL_NO;
  LL_GPIO_Init(USER_SW_GPIO_Port, &GPIO_InitStruct);

  /**/
  LL_SYSCFG_SetEXTISource(LL_SYSCFG_EXTI_PORTB, LL_SYSCFG_EXTI_LINE9);

  /**/
  EXTI_InitStruct.Line_0_31 = LL_EXTI_LINE_9;
  EXTI_InitStruct.LineCommand = ENABLE;
  EXTI_InitStruct.Mode = LL_EXTI_MODE_IT;
  EXTI_InitStruct.Trigger = LL_EXTI_TRIGGER_RISING;
  LL_EXTI_Init(&EXTI_InitStruct);

  /**/
  LL_GPIO_SetPinPull(ADIS_DR_GPIO_Port, ADIS_DR_Pin, LL_GPIO_PULL_UP);

  /**/
  LL_GPIO_SetPinMode(ADIS_DR_GPIO_Port, ADIS_DR_Pin, LL_GPIO_MODE_INPUT);

  /* EXTI interrupt init*/
  NVIC_SetPriority(EXTI9_5_IRQn, NVIC_EncodePriority(NVIC_GetPriorityGrouping(),2, 0));
  NVIC_EnableIRQ(EXTI9_5_IRQn);

}

void Error_Handler(void)
{
  __disable_irq();
  while (1)
  {
  }
}
